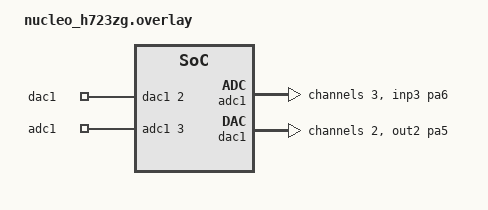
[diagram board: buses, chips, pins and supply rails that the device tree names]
/*
 * Copyright (c) 2021 STMicroelectronics
 *
 * SPDX-License-Identifier: Apache-2.0
 */

/*
 * DAC output on PA5
 * ADC input read from PA6
 * Add a jumper between those two pins to run this test.
 */
/ {
	zephyr,user {
		io-channels = <&dac1 2 &adc1 3>;
		io-channel-names = "dac1", "adc1";
	};
};

&adc1 {
	status = "okay";
	st,adc-clock-source = "SYNC";
	st,adc-prescaler = <4>;
	pinctrl-0 = <&adc1_inp3_pa6>;
	pinctrl-names = "default";

	#address-cells = <1>;
	#size-cells = <0>;

	channel@3 {
		reg = <3>;
		zephyr,gain = "ADC_GAIN_1";
		zephyr,reference = "ADC_REF_INTERNAL";
		zephyr,resolution = <12>;
		zephyr,acquisition-time = <ADC_ACQ_TIME_MAX>;
	};
};

&dac1 {
	status = "okay";
	pinctrl-0 = <&dac1_out2_pa5>;
	pinctrl-names = "default";

	#address-cells = <1>;
	#size-cells = <0>;

	channel@2 {
		reg = <2>;
		zephyr,resolution = <12>;
	};
};
